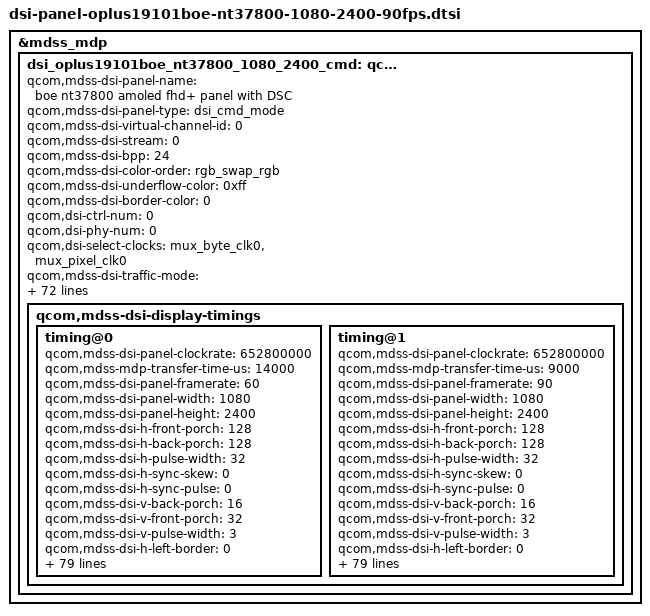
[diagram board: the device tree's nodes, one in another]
&mdss_mdp {
	dsi_oplus19101boe_nt37800_1080_2400_cmd: qcom,mdss_dsi_oplus19101boe_nt37800_1080_2400_cmd {
		qcom,mdss-dsi-panel-name =
		  "boe nt37800 amoled fhd+ panel with DSC";
		qcom,mdss-dsi-panel-type = "dsi_cmd_mode";
		qcom,mdss-dsi-virtual-channel-id = <0>;
		qcom,mdss-dsi-stream = <0>;
		qcom,mdss-dsi-bpp = <24>;
		qcom,mdss-dsi-color-order = "rgb_swap_rgb";
		qcom,mdss-dsi-underflow-color = <0xff>;
		qcom,mdss-dsi-border-color = <0>;

		qcom,dsi-ctrl-num = <0>;
		qcom,dsi-phy-num = <0>;
		qcom,dsi-select-clocks = "src_byte_clk0", "src_pixel_clk0";

		qcom,mdss-dsi-traffic-mode = "non_burst_sync_event";
		qcom,mdss-dsi-lane-map = "lane_map_0123";
		qcom,mdss-dsi-bllp-eof-power-mode;
		qcom,mdss-dsi-bllp-power-mode;
		qcom,mdss-dsi-lane-0-state;
		qcom,mdss-dsi-lane-1-state;
		qcom,mdss-dsi-lane-2-state;
		qcom,mdss-dsi-lane-3-state;
		qcom,mdss-dsi-dma-trigger = "trigger_sw";
		qcom,mdss-dsi-mdp-trigger = "none";
		qcom,mdss-dsi-reset-sequence = <1 10>, <0 10>, <1 10>;
		qcom,mdss-dsi-te-pin-select = <1>;
		qcom,mdss-dsi-wr-mem-start = <0x2c>;
		qcom,mdss-dsi-wr-mem-continue = <0x3c>;
		qcom,mdss-dsi-te-dcs-command = <1>;
		qcom,mdss-dsi-te-check-enable;
		qcom,mdss-dsi-te-using-te-pin;
		//qcom,mdss-dsi-lp11-init;
		qcom,mdss-dsi-panel-hdr-enabled;
		qcom,mdss-dsi-panel-hdr-color-primaries = <15000 15500 34000
			16000 13250 34500 7500 3000>;
		qcom,mdss-dsi-panel-peak-brightness = <4300000>;
		qcom,mdss-dsi-panel-blackness-level = <1023>;
		qcom,mdss-pan-physical-width-dimension = <68>;
		qcom,mdss-pan-physical-height-dimension = <152>;
		qcom,esd-check-enabled;
		qcom,mdss-dsi-panel-status-check-mode = "reg_read";
		qcom,mdss-dsi-panel-status-command = [06 01 00 01 05 00 02 0A 00];
		qcom,mdss-dsi-panel-status-command-state = "dsi_hs_mode";
		qcom,mdss-dsi-panel-status-value = <0x9C>;
		qcom,mdss-dsi-panel-status-read-length = <1>;

		qcom,mdss-dsi-display-timings {
			timing@0{
				qcom,mdss-dsi-panel-clockrate = <652800000>;
				qcom,mdss-mdp-transfer-time-us = <14000>;
				qcom,mdss-dsi-panel-framerate = <60>; /* 60 FPS */
				qcom,mdss-dsi-panel-width = <1080>;
				qcom,mdss-dsi-panel-height = <2400>;
				qcom,mdss-dsi-h-front-porch = <128>;
				qcom,mdss-dsi-h-back-porch = <128>;
				qcom,mdss-dsi-h-pulse-width = <32>;
				qcom,mdss-dsi-h-sync-skew = <0>;
				qcom,mdss-dsi-h-sync-pulse = <0>;
				qcom,mdss-dsi-v-back-porch = <16>;
				qcom,mdss-dsi-v-front-porch = <32>;
				qcom,mdss-dsi-v-pulse-width = <3>;
				qcom,mdss-dsi-h-left-border = <0>;
				qcom,mdss-dsi-h-right-border = <0>;
				qcom,mdss-dsi-v-top-border = <0>;
				qcom,mdss-dsi-v-bottom-border = <0>;
				qcom,mdss-dsi-panel-jitter = <0x4 0x1>;
				oplus,fod-on-vblank = <0>;
				oplus,fod-off-vblank = <0>;
				qcom,mdss-dsi-timing-switch-command = [
					39 01 00 00 00 00 06 F0 55 AA 52 08 00 /* 60 FPS */
					15 01 00 00 00 00 02 6F 0E
					15 01 00 00 00 00 02 BA 18
					15 01 00 00 00 00 02 6F 03
					39 01 00 00 00 00 04 C0 80 00 00
					39 01 00 00 10 00 02 26 01 /* 60 FPS */
				];
				qcom,mdss-dsi-on-command = [
					39 01 00 00 00 00 05 FF AA 55 A5 80
					15 01 00 00 00 00 02 6F 64
					15 01 00 00 00 00 02 F4 06
					/* 101.6Mhz */
					39 01 00 00 00 00 05 FF AA 55 A5 81
					15 01 00 00 00 00 02 6F 05
					15 01 00 00 00 00 02 FD 00
					15 01 00 00 00 00 02 6F 06
					15 01 00 00 00 00 02 FD D8
					39 01 00 00 00 00 06 F0 55 AA 52 08 00
					39 01 00 00 00 00 09 BA 01 D4 00 08 00 08 80 01
					15 01 00 00 00 00 02 6F 08
					39 01 00 00 00 00 09 BA 01 D4 00 08 00 08 00 10
					15 01 00 00 00 00 02 6F 10
					39 01 00 00 00 00 0F BA 01 D4 00 08 00 08 02 30 00 08 00 08 00 00
					39 01 00 00 00 00 09 BB 01 D4 00 08 00 08 00 31
					39 01 00 00 00 00 03 C1 00 70
					39 01 00 00 00 00 03 C0 76 33
					39 01 00 00 00 00 06 F0 55 AA 52 08 03
					39 01 00 00 00 00 0B B2 00 00 0A 06 01 00 00 0A 06 01
					39 01 00 00 00 00 0B B3 00 00 00 04 26 00 00 00 04 26
					39 01 00 00 00 00 16 B6 03 00 00 00 00 00 00 00 08 00 00 00 00 00 08 00 00 00 00 00 00
					39 01 00 00 00 00 08 BB 11 00 23 63 00 23 63
					39 01 00 00 00 00 08 BC 22 10 19 5A 00 19 5A
					39 01 00 00 00 00 06 F0 55 AA 52 08 01
					39 01 00 00 00 00 03 B3 14 14
					39 01 00 00 00 00 07 B7 1A 1A 1A 1A 1A 1A
					39 01 00 00 00 00 08 D2 00 41 1F 41 25 00 67
					/* mipi 652.8Mhz */
					39 01 00 00 00 00 05 ff aa 55 a5 81
					15 01 00 00 00 00 02 6f 09
					15 01 00 00 00 00 02 fd ac
					39 01 00 00 00 00 06 f0 55 aa 52 08 01
					39 01 00 00 00 00 08 c3 99 00 fc 0f 21 01 00
					/* DVDD strong */
					39 01 00 00 00 00 05 FF AA 55 A5 81
					15 01 00 00 00 00 02 FB 20
					15 01 00 00 00 00 02 6F 06
					15 01 00 00 00 00 02 FB 04
					15 01 00 00 00 00 02 6F 09
					15 01 00 00 00 00 02 FB 04
					/*AVEE pump*/
					39 01 00 00 00 00 06 F0 55 AA 52 08 01
					39 01 00 00 00 00 03 B2 02 02
					39 01 00 00 00 00 02 CE 04
					/* Fast Discharge */
					39 01 00 00 00 00 06 F0 55 AA 52 08 01
					39 01 00 00 00 00 02 C7 FA
					/* HW Round */
					39 01 00 00 00 00 06 F0 55 AA 52 08 07
					15 01 00 00 00 00 02 C0 11
					39 01 00 00 00 00 27 C1 60 3C 03 10 F7 78 05 F1 3F FD D2 A0 3F FB CF E8 00 00 63 10 90 1A 00 1B 00 00 76 1C 00 00 00 00 1A 1C F7 FF FF FF
					39 01 00 00 00 00 27 C2 48 3C 01 69 FC 24 02 A4 3F FD 61 7C 3F FE 5E C8 00 00 40 60 24 4F 00 00 1D 00 1A 6C F7 FF FF F7 FF FF F7 FF FF FF
					39 01 00 00 00 00 27 C3 64 00 03 10 07 A8 04 C9 3F FC FC 40 00 03 03 C0 00 00 00 00 00 1C 90 1B 43 90 76 5F 90 00 43 90 1A 5E F7 FF FF FF
					39 01 00 00 00 00 27 C4 4C 00 01 90 04 10 02 A4 3F FC 08 60 00 00 00 00 00 00 00 00 00 50 80 00 F2 90 1A 42 90 00 43 90 1A 5E F7 FF FF FF
					39 01 00 00 00 00 27 C5 6A 3C 02 D9 F8 68 05 10 00 00 CD 08 00 05 44 50 7F FF 63 61 00 00 93 C2 44 94 1A 5F 94 1B 44 94 36 5E F7 FF FF FF
					39 01 00 00 00 00 27 C6 4A 3C 02 D9 FA F0 02 40 00 03 D3 98 00 00 B7 F0 7F FF 8C 22 D0 51 84 1B F2 94 37 43 F7 FF FF F7 FF FF F7 FF FF FF
					39 01 00 00 00 00 27 C7 66 00 02 71 07 08 05 10 00 00 18 C8 3F F9 FF 90 00 00 00 00 00 1B 03 C2 00 04 1A 1B 04 1B 00 04 37 1B F7 FF FF FF
					39 01 00 00 00 00 27 C8 46 00 05 F1 06 18 01 90 00 01 BC F0 3F FE 03 80 00 00 00 00 00 02 04 1B 1C 04 37 6D F7 FF FF F7 FF FF F7 FF FF FF
					39 01 00 00 00 00 27 C9 41 00 03 C1 00 00 03 C1 3F FF 17 42 3F FF 17 42 00 00 0E 17 81 09 00 43 24 00 62 43 F7 FF FF F7 FF FF F7 FF FF FF
					39 01 00 00 00 00 27 CA 4D 00 03 C1 00 00 03 C1 3F FF 17 42 00 00 00 00 00 00 00 00 00 15 00 43 44 00 62 63 F7 FF FF F7 FF FF F7 FF FF FF
					39 01 00 00 00 00 27 CB 4B 00 03 C1 00 00 03 C1 00 00 00 00 00 00 00 00 7F FF F1 E8 7F 15 00 63 44 00 82 63 F7 FF FF F7 FF FF F7 FF FF FF
					39 01 00 00 00 00 27 CC 47 00 03 C1 00 00 03 C1 00 00 00 00 3F FF 17 42 00 00 00 00 00 09 00 63 24 00 82 43 F7 FF FF F7 FF FF F7 FF FF FF
					39 01 00 00 00 00 27 CD 00 00 00 00 00 00 00 00 00 00 00 00 00 00 00 00 00 00 00 00 00 00 F7 FF FF F7 FF FF F7 FF FF F7 FF FF F7 FF FF FF
					39 01 00 00 00 00 27 CE 00 00 00 00 00 00 00 00 00 00 00 00 00 00 00 00 00 00 00 00 00 00 F7 FF FF F7 FF FF F7 FF FF F7 FF FF F7 FF FF FF
					39 01 00 00 00 00 27 CF 00 00 00 00 00 00 00 00 00 00 00 00 00 00 00 00 00 00 00 00 00 00 F7 FF FF F7 FF FF F7 FF FF F7 FF FF F7 FF FF FF
					39 01 00 00 00 00 27 D0 00 00 00 00 00 00 00 00 00 00 00 00 00 00 00 00 00 00 00 00 00 00 F7 FF FF F7 FF FF F7 FF FF F7 FF FF F7 FF FF FF  /* HW Round */
					39 01 00 00 00 00 05 FF AA 55 A5 80
					15 01 00 00 00 00 02 6F 0A
					15 01 00 00 00 00 02 FC 02
					39 01 00 00 00 00 05 FF AA 55 A5 00
					39 01 00 00 00 00 06 F0 55 AA 52 08 00
					15 01 00 00 00 00 02 B2 01
					15 01 00 00 00 00 02 6F 0E
					15 01 00 00 00 00 02 BA 18
					15 01 00 00 00 00 02 6F 03
					39 01 00 00 00 00 04 C0 80 00 00
					39 01 00 00 00 00 02 26 01
					15 01 00 00 00 00 01 35
					39 01 00 00 00 00 05 3B 00 08 00 08
					15 01 00 00 00 00 02 53 20
					39 01 00 00 00 00 05 51 00 00 0F FF
					39 01 00 00 00 00 05 2A 00 00 04 37
					39 01 00 00 00 00 05 2b 00 00 09 5F
					39 01 00 00 00 00 13 93 89 28 00 14 02 00 02 0e 01 e8 00 07 05 0e 05 16 10 f0
					15 01 00 00 00 00 02 90 01
					15 01 00 00 00 00 02 03 11
					05 01 00 00 00 00 01 2c
					39 01 00 00 00 00 06 F0 55 AA 52 08 00
					39 01 00 00 00 00 03 C0 76 33
					39 01 00 00 00 00 06 F0 55 AA 52 08 01
					39 01 00 00 00 00 04 D2 00 41 10
					05 01 00 00 A0 00 01 11
					];
				qcom,mdss-dsi-post-on-backlight = [
					05 01 00 00 00 00 01 29
					];
				qcom,mdss-dsi-off-command = [
					39 01 00 00 00 00 06 F0 55 AA 52 08 01
					39 01 00 00 00 00 02 CE 0C
					05 01 00 00 0A 00 01 28
					05 01 00 00 78 00 01 10];
				qcom,mdss-dsi-lp1-command = [    /* AOD ON */
					39 01 00 00 00 00 06 F0 55 AA 52 08 00  /*Need 90 FPS when AOD in*/
					15 01 00 00 00 00 02 6F 03
					39 01 00 00 00 00 04 C0 00 00 00
					15 01 00 00 14 00 02 26 02  /* Need 90 FPS when AOD in*/
					05 01 00 00 00 00 01 39
					15 01 00 00 00 00 02 65 01
					05 01 00 00 00 00 01 2C
					];
				qcom,mdss-dsi-nolp-command = [    /* AOD OFF */
					39 01 00 00 00 00 06 F0 55 AA 52 08 00 /* 60 FPS */
					15 01 00 00 00 00 02 6F 0E
					15 01 00 00 00 00 02 BA 18
					15 01 00 00 00 00 02 6F 03
					39 01 00 00 00 00 04 C0 80 00 00
					39 01 00 00 00 00 02 26 01 /* 60 FPS */
					15 01 00 00 00 00 02 65 00
					05 01 00 00 00 00 01 38
					05 01 00 00 00 00 01 2C
					];
				qcom,mdss-dsi-aod-hbm-on-command = [  /*AOD->HBM ON PANEL FINGERPRINT OFF*/
					39 01 00 00 00 00 06 F0 55 AA 52 08 00 /* 60 FPS */
					15 01 00 00 00 00 02 6F 0E
					15 01 00 00 00 00 02 BA 18
					15 01 00 00 00 00 02 6F 03
					39 01 00 00 00 00 04 C0 80 00 00
					39 01 00 00 00 00 02 26 01 /* 60 FPS */
					15 01 00 00 00 00 02 65 00
					05 01 00 00 00 00 01 38
					05 01 00 00 00 00 01 2C
					39 01 00 00 00 00 03 51 0F FF
				];
				qcom,mdss-dsi-aod-hbm-off-command = [  /*AOD->HBM ON PANEL FINGERPRINT OFF*/
					39 01 00 00 00 00 06 F0 55 AA 52 08 00  /*Need 90 FPS when AOD in*/
					15 01 00 00 00 00 02 6F 03
					39 01 00 00 00 00 04 C0 00 00 00
					15 01 00 00 14 00 02 26 02  /* Need 90 FPS when AOD in*/
					05 01 00 00 00 00 01 39
					15 01 00 00 00 00 02 65 01
					05 01 00 00 00 00 01 2C
					39 01 00 00 00 00 03 51 00 01
				];
				qcom,mdss-dsi-hbm-on-command = [
					39 01 00 00 22 00 03 51 0F FF
					];
				qcom,mdss-dsi-normal-hbm-on-command = [
					39 01 00 00 00 00 03 51 0F FF
					];
				qcom,mdss-dsi-aod-high-mode-command = [
					/* AOD 50nit */
					39 01 00 00 00 00 06 F0 55 AA 52 08 00
					15 01 00 00 00 00 02 6F 24
					39 01 00 00 00 00 0B B4 00 28 00 28 00 28 00 28 00 28
					];
				qcom,mdss-dsi-aod-low-mode-command = [
					/* AOD 10nit */
					39 01 00 00 00 00 06 F0 55 AA 52 08 00
					15 01 00 00 00 00 02 6F 24
					39 01 00 00 00 00 0B B4 07 80 07 80 07 80 07 80 07 80
					];
				qcom,mdss-dsi-seed-0-command = [
					39 01 00 00 00 00 02 55 80
					39 01 00 00 00 00 06 F0 55 AA 52 08 00
					39 01 00 00 00 00 19 CC 31 33 32 33 33 34 35 35 36 37 36 37 38 38 37 36 33 50 60 70 58 68 78 77
					39 01 00 00 00 00 12 CD 2E 6A 78 51 44 7A 2F 2C 7D 2D 05 63 36 5D 73 48 26
					39 01 00 00 00 00 68 CE 00 6B 49 55 52 57 5B 5F 60 60 60 5C 5A 5A 56 52 52 54 97 4E 43 45 49 4D 47 47 56 5E 57 63 7B 85 88 87 74 5E 41 4B 56 3F 45 44 3D 3A 3D 31 36 3C 37 37 38 3D 43 41 43 53 57 5C 60 5F 60 5F 59 58 58 53 55 58 56 1A 45 3B 39 3E 38 43 43 46 4C 47 4A 50 4E 52 53 4D 59 3F 48 54 5A 54 53 4C 51 50 4B 48 45 3F 39 37 3C
					39 01 00 00 00 00 69 CF 40 40 40 40 40 40 40 40 40 40 40 40 40 40 40 40 40 40 40 40 40 40 40 40 40 40 40 40 40 40 40 40 40 40 40 40 40 40 40 40 40 40 40 40 40 40 40 40 40 40 40 40 40 40 40 40 40 40 40 40 40 40 40 40 40 40 40 40 40 40 40 40 40 40 40 40 40 40 40 40 40 40 40 40 40 40 40 40 40 40 40 40 40 40 40 40 40 40 40 40 40 40 40 40
					39 01 00 00 00 00 07 D0 01 00 FE 77 04 1D
					39 01 00 00 00 00 2e D1 4F 4B 40 50 53 53 50 62 4A 70 7F 7F 7F 7F 77 69 40 41 42 40 42 61 40 40 77 55 55 77 65 66 62 66 51 55 45 55 00 06 0C 03 09 0F 68 88 00
					39 01 00 00 00 00 34 D2 01 08 40 83 88 88 83 83 7C 76 73 6D 7C 7A 7C 80 87 87 89 83 8A 85 82 7B 7D 7B 7E 8F 82 84 84 82 7F 7E 7A 56 5F 63 6D 80 92 99 9E B1 8B 84 80 7C 7A 7F 88
					39 01 00 00 00 00 07 D3 30 52 74 76 50 10
					39 01 00 00 00 00 1a D4 0F 76 76 05 0D 14 0F 18 1F 05 0D 14 03 07 0A A0 55 FF 79 44 12 00 00 80 00
					39 01 00 00 00 00 67 D5 00 00 00 00 00 00 40 40 40 40 40 40 40 40 40 40 40 40 40 40 40 40 40 40 40 40 40 40 40 40 40 40 40 40 40 40 40 40 40 40 40 40 40 40 40 40 40 40 40 40 40 40 40 40 40 40 40 40 40 40 40 40 40 40 40 40 40 40 40 40 40 40 40 40 40 40 40 40 40 40 40 40 40 40 40 40 40 40 40 40 40 40 40 40 40 40 40 40 40 40 40 40
					39 01 00 00 00 00 4e D6 00 00 00 00 00 00 00 00 00 00 00 00 40 40 40 40 40 40 40 40 40 40 40 40 40 40 40 40 40 40 40 40 40 40 40 40 40 40 40 40 40 40 40 40 40 40 40 40 40 40 40 40 40 40 40 40 40 40 40 40 40 40 40 40 40 40 40 40 40 40 40 40 40 40 40 40 40
					39 01 00 00 00 00 32 D7 30 34 3A 3C 3B 3D 41 48 4D 46 41 45 3D 38 3B 3C 3D 3D 40 45 47 44 41 43 3D 3C 3C 3C 3E 3C 3F 42 42 42 42 42 3E 3E 3E 3E 3F 3E 3F 41 41 41 41 41 3F
					39 01 00 00 00 00 19 DE 33 63 33 33 33 30 30 33 33 33 30 33 00 00 00 00 00 00 00 00 00 00 00 00
					];
				qcom,mdss-dsi-seed-1-command = [
					39 01 00 00 00 00 02 55 80
					39 01 00 00 00 00 06 F0 55 AA 52 08 00
					39 01 00 00 00 00 19 CC 2D 2A 30 2B 2C 2B 2C 2C 2C 2E 2E 2F 2E 2D 2B 29 27 50 60 70 58 68 78 77
					39 01 00 00 00 00 12 CD 22 50 67 39 22 2D 71 73 21 6A 4A 42 6E 0D 7C 54 45
					39 01 00 00 00 00 68 CE 00 5A 60 5F 4B 51 4A 4B 46 44 46 42 41 3C 39 38 3A 3F 4B 45 5A 4F 4D 55 52 4B 54 64 65 6E 6D 6A 66 61 5D 39 37 46 3D 3B 37 3D 36 34 3F 3E 40 3D 40 40 41 42 39 3F 5A 45 49 42 47 45 41 4C 4A 49 45 43 41 40 40 56 4E 59 4A 4C 4A 50 43 43 46 41 3F 3C 39 38 3B 3E 56 4F 5F 49 49 43 44 3B 3D 40 3D 40 3C 3D 3C 3D 42
					39 01 00 00 00 00 69 CF 40 40 40 40 40 40 40 40 40 40 40 40 40 40 40 40 40 40 40 40 40 40 40 40 40 40 40 40 40 40 40 40 40 40 40 40 40 40 40 40 40 40 40 40 40 40 40 40 40 40 40 40 40 40 40 40 40 40 40 40 40 40 40 40 40 40 40 40 40 40 40 40 40 40 40 40 40 40 40 40 40 40 40 40 40 40 40 40 40 40 40 40 40 40 40 40 40 40 40 40 40 40 40 40
					39 01 00 00 00 00 07 D0 01 00 FE 77 04 1D
					39 01 00 00 00 00 2e D1 60 61 66 72 72 77 7F 72 72 7F 7F 7F 7F 7F 74 5F 51 4F 55 5F 68 66 63 5E 66 46 44 44 54 55 42 50 51 75 74 57 00 06 0C 03 09 0F 68 88 00
					39 01 00 00 00 00 34 D2 01 00 40 8B 8E 8E 88 83 77 69 56 4E 58 64 6F 85 92 94 8E 8F 85 74 6E 66 79 7A 79 9A 7B 80 81 81 80 8F 60 2D 06 38 4F 87 A7 AF A0 B1 87 76 6E 6A 80 8F 9E
					39 01 00 00 00 00 07 D3 30 52 74 76 50 10
					39 01 00 00 00 00 1a D4 0F 76 76 05 0D 14 0F 18 1F 05 0D 14 03 07 0A A0 55 FF 79 44 12 00 00 80 00
					39 01 00 00 00 00 67 D5 00 00 00 00 00 00 40 40 40 40 40 40 40 40 40 40 40 40 40 40 40 40 40 40 40 40 40 40 40 40 40 40 40 40 40 40 40 40 40 40 40 40 40 40 40 40 40 40 40 40 40 40 40 40 40 40 40 40 40 40 40 40 40 40 40 40 40 40 40 40 40 40 40 40 40 40 40 40 40 40 40 40 40 40 40 40 40 40 40 40 40 40 40 40 40 40 40 40 40 40 40 40
					39 01 00 00 00 00 4e D6 00 00 00 00 00 00 00 00 00 00 00 00 40 40 40 40 40 40 40 40 40 40 40 40 40 40 40 40 40 40 40 40 40 40 40 40 40 40 40 40 40 40 40 40 40 40 40 40 40 40 40 40 40 40 40 40 40 40 40 40 40 40 40 40 40 40 40 40 40 40 40 40 40 40 40 40 40
					39 01 00 00 00 00 32 D7 30 39 3C 40 43 46 4B 4F 53 39 49 4E 43 38 3C 3F 41 41 46 4A 4B 3D 44 48 3F 38 3C 3E 40 3D 42 45 44 40 40 42 3C 3C 3E 3F 40 3E 41 42 42 40 40 41 3E
					39 01 00 00 00 00 19 DE 43 45 33 43 40 00 33 34 33 33 37 43 00 00 00 00 00 00 00 00 00 00 00 00
					];
				qcom,mdss-dsi-spr-0-command = [
					39 01 00 00 00 00 06 F0 55 AA 52 08 07
					39 01 00 00 00 00 07 B0 A4 40 70 60 00 00
					39 01 00 00 00 00 18 B1 08 18 00 18 08 00 00 00 00 00 00 00 00 00 00 00 00 00 00 00 00 00 00
					39 01 00 00 00 00 B5 B2 20 20 20 20 20 20 20 20 20 20 20 20 20 20 20 20 20 20 20 20 20 20 20 20 20 20 20 20 20 20 20 20 20 20 20 20 20 20 20 20 20 20 20 20 20 20 20 20 20 20 20 20 20 20 32 32 32 32 32 32 32 32 32 00 00 00 00 00 00 00 00 00 32 32 32 32 32 32 32 32 32 00 00 00 00 00 00 00 00 00 32 32 32 32 32 32 32 32 32 00 00 00 00 00 00 00 00 00 32 32 32 32 32 32 32 32 32 00 00 00 00 00 00 00 00 00 32 32 32 32 32 32 32 32 32 00 00 00 00 00 00 00 00 00 32 32 32 32 32 32 32 32 32 00 00 00 00 00 00 00 00 00 00 00 20 00 20 00 00 00 00 00 32 00 00 00 32 00 00 00
					39 01 00 00 00 00 5B B3 00 00 00 00 00 00 00 00 00 00 00 00 00 00 00 00 00 00 00 00 00 00 00 00 00 00 00 00 00 00 00 00 00 00 00 00 00 00 00 00 00 00 00 00 00 00 00 00 00 00 00 00 00 00 00 00 00 00 00 00 00 00 00 00 00 00 00 00 00 00 00 00 00 00 00 00 00 00 00 00 00 00 00 00 00 00 00 00 00 00
					39 01 00 00 00 00 1B B4 C0 00 00 00 00 00 00 00 00 00 00 00 00 00 80 80 80 80 40 80 80 80 80 80 40 80
					39 01 00 00 00 00 49 B5 00 00 00 00 00 00 00 00 00 00 00 00 00 00 00 00 00 00 00 00 00 00 04 00 00 00 00 00 00 00 00 00 00 00 00 00 00 00 00 00 00 00 00 00 00 00 00 00 00 00 00 00 00 00 00 00 00 00 00 00 00 00 00 00 00 00 00 00 00 00 00 00
					39 01 00 00 00 00 25 B6 00 00 00 00 00 00 00 00 00 00 00 00 00 00 00 00 00 00 00 00 00 00 00 00 E0 00 E0 00 00 00 E0 00 E0 00 00 00
					39 01 00 00 00 00 50 B7 24 84 00 08 01 08 01 00 00 00 00 00 00 00 00 00 00 00 00 00 00 00 00 00 00 00 00 00 00 00 00 00 00 00 00 00 00 00 00 00 00 00 00 FD 58 0E A5 78 2A 1A 77 FE CF 7E 0D E5 B2 B7 87 CC 14 80 80 80 80 80 80 80 80 80 80 80 80 80 80 80 80 80 80
					39 01 00 00 00 00 58 B8 00 00 00 00 00 00 00 00 00 00 00 00 00 00 00 00 00 00 00 02 02 00 00 00 00 00 00 00 00 00 00 00 00 00 00 00 00 00 00 00 00 00 00 00 00 00 00 00 00 00 00 00 00 00 00 00 00 00 00 00 00 00 00 00 00 00 00 00 00 00 00 00 00 00 00 00 00 00 00 00 00 00 00 00 00 00 00
					39 01 00 00 00 00 C1 B9 00 00 00 00 00 00 00 00 00 00 00 00 00 00 00 00 00 00 00 00 00 00 00 00 00 00 00 00 00 00 00 00 00 00 00 00 00 00 00 00 00 00 00 00 00 00 00 00 00 00 00 00 00 00 00 00 00 00 00 00 00 00 00 00 00 00 00 00 00 00 00 00 00 00 00 00 00 00 00 00 00 00 00 00 00 00 00 00 00 00 00 00 00 00 00 00 00 00 00 00 00 00 00 00 00 00 00 00 00 00 00 00 00 00 00 00 00 00 00 00 00 00 00 00 00 00 00 00 00 00 00 00 00 00 00 00 00 00 00 00 00 00 00 00 00 00 00 00 00 00 00 00 00 00 00 00 00 00 00 00 00 00 00 00 00 00 00 00 00 00 00 00 00 00 00 00 00 00 00 00 00 00 00 00 00 00 00 00 00 00 00 00
					39 01 00 00 00 00 20 BA 00 00 00 00 00 00 00 00 00 00 00 00 00 00 00 00 00 00 00 00 00 00 00 00 00 00 00 00 00 00 00
					39 01 00 00 00 00 88 BB 00 00 00 00 00 00 00 00 00 00 00 00 00 00 00 00 00 00 00 00 00 00 00 00 00 00 00 00 00 00 00 00 00 00 00 00 00 00 00 00 00 00 00 00 00 00 00 00 00 00 00 00 00 00 00 00 00 00 00 00 00 00 00 00 00 00 00 00 00 00 00 00 00 00 00 00 00 00 00 00 00 00 00 00 00 00 00 00 00 00 00 00 00 00 00 00 00 00 00 00 00 00 00 00 00 00 00 00 00 00 00 00 00 00 00 00 00 00 00 00 00 00 00 00 00 00 00 00 00 00 00 00 00 00 00
					39 01 00 00 00 00 14 BC 00 00 00 00 00 00 00 00 00 00 00 00 00 00 00 00 00 00 00
					39 01 00 00 00 00 0D BD 00 00 00 00 00 00 00 00 00 00 00 00
					];
				qcom,mdss-dsi-spr-1-command = [
					39 01 00 00 00 00 06 F0 55 AA 52 08 07
					39 01 00 00 00 00 07 B0 A4 40 70 60 00 00
					39 01 00 00 00 00 03 B7 80 90
					39 01 00 00 00 00 02 6F 43
					39 01 00 00 00 00 04 B7 80 70 80
					39 01 00 00 00 00 02 6F 46
					39 01 00 00 00 00 04 B7 80 70 80
					39 01 00 00 00 00 18 B1 0C 1C 00 1C 0C 00 00 00 00 00 00 00 00 00 00 00 00 00 00 00 00 00 00
					39 01 00 00 00 00 B5 B2 22 22 22 22 22 22 22 22 22 22 22 22 22 22 22 22 22 22 00 00 00 00 00 00 00 00 00 22 22 22 22 22 22 22 22 22 22 22 22 22 22 22 22 22 22 00 00 00 00 00 00 00 00 00 3A 3A 3A 3A 3A 3A 3A 3A 3A 05 05 05 05 05 05 05 05 05 3A 3A 3A 3A 3A 3A 3A 3A 3A 05 05 05 05 05 05 05 05 05 00 00 00 00 00 00 00 00 00 00 00 00 00 00 00 00 00 00 3A 3A 3A 3A 3A 3A 3A 3A 3A 05 05 05 05 05 05 05 05 05 3A 3A 3A 3A 3A 3A 3A 3A 3A 05 05 05 05 05 05 05 05 05 00 00 00 00 00 00 00 00 00 00 00 00 00 00 00 00 00 00 00 00 00 00 00 00 00 00 00 00 00 00 00 00 00 00 00 00
					39 01 00 00 00 00 5B B3 00 00 00 00 00 00 00 00 00 00 00 00 00 00 00 00 00 00 00 00 00 00 00 00 00 00 00 00 00 00 00 00 00 00 00 00 00 00 00 00 00 00 00 00 00 00 00 00 00 00 00 00 00 00 00 00 00 00 00 00 00 00 00 00 00 00 00 00 00 00 00 00 00 00 00 00 00 00 00 00 00 00 00 00 00 00 00 00 00 00
					39 01 00 00 00 00 1B B4 C0 00 00 00 00 00 00 00 00 00 00 00 00 00 80 68 80 80 60 80 80 60 80 80 A0 80
					39 01 00 00 00 00 49 B5 00 00 00 00 00 00 00 00 00 00 00 00 00 00 00 00 00 00 00 00 00 00 04 00 00 00 00 00 00 00 00 00 00 00 00 00 00 00 00 00 00 00 00 00 00 00 00 00 00 00 00 00 00 00 00 00 00 00 00 00 00 00 00 00 00 00 00 00 00 00 00 00
					39 01 00 00 00 00 25 B6 00 00 00 00 00 00 00 00 00 00 00 00 00 00 00 00 00 00 00 00 00 00 00 00 E0 00 E0 00 00 00 E0 00 E0 00 00 00
					39 01 00 00 00 00 58 B8 00 00 00 00 00 00 00 00 00 00 00 00 00 00 00 00 00 00 00 02 02 00 00 00 00 00 00 00 00 00 00 00 00 00 00 00 00 00 00 00 00 00 00 00 00 00 00 00 00 00 00 00 00 00 00 00 00 00 00 00 00 00 00 00 00 00 00 00 00 00 00 00 00 00 00 00 00 00 00 00 00 00 00 00 00 00 00
					39 01 00 00 00 00 C1 B9 00 00 00 00 00 00 00 00 00 00 00 00 00 00 00 00 00 00 00 00 00 00 00 00 00 00 00 00 00 00 00 00 00 00 00 00 00 00 00 00 00 00 00 00 00 00 00 00 00 00 00 00 00 00 00 00 00 00 00 00 00 00 00 00 00 00 00 00 00 00 00 00 00 00 00 00 00 00 00 00 00 00 00 00 00 00 00 00 00 00 00 00 00 00 00 00 00 00 00 00 00 00 00 00 00 00 00 00 00 00 00 00 00 00 00 00 00 00 00 00 00 00 00 00 00 00 00 00 00 00 00 00 00 00 00 00 00 00 00 00 00 00 00 00 00 00 00 00 00 00 00 00 00 00 00 00 00 00 00 00 00 00 00 00 00 00 00 00 00 00 00 00 00 00 00 00 00 00 00 00 00 00 00 00 00 00 00 00 00 00 00 00
					39 01 00 00 00 00 20 BA 00 00 00 00 00 00 00 00 00 00 00 00 00 00 00 00 00 00 00 00 00 00 00 00 00 00 00 00 00 00 00
					39 01 00 00 00 00 88 BB 00 00 00 00 00 00 00 00 00 00 00 00 00 00 00 00 00 00 00 00 00 00 00 00 00 00 00 00 00 00 00 00 00 00 00 00 00 00 00 00 00 00 00 00 00 00 00 00 00 00 00 00 00 00 00 00 00 00 00 00 00 00 00 00 00 00 00 00 00 00 00 00 00 00 00 00 00 00 00 00 00 00 00 00 00 00 00 00 00 00 00 00 00 00 00 00 00 00 00 00 00 00 00 00 00 00 00 00 00 00 00 00 00 00 00 00 00 00 00 00 00 00 00 00 00 00 00 00 00 00 00 00 00 00 00
					39 01 00 00 00 00 14 BC 00 00 00 00 00 00 00 00 00 00 00 00 00 00 00 00 00 00 00
					39 01 00 00 00 00 0D BD 00 00 00 00 00 00 00 00 00 00 00 00
					];
				qcom,mdss-dsi-spr-2-command = [
					39 01 00 00 00 00 06 F0 55 AA 52 08 07
					39 01 00 00 00 00 07 B0 A4 40 70 60 00 00
					39 01 00 00 00 00 18 B1 08 18 00 18 08 00 00 00 00 00 00 00 00 00 00 00 00 00 00 00 00 00 00
					39 01 00 00 00 00 B5 B2 20 20 20 20 20 20 20 20 20 20 20 20 20 20 20 20 20 20 20 20 20 20 20 20 20 20 20 20 20 20 20 20 20 20 20 20 20 20 20 20 20 20 20 20 20 20 20 20 20 20 20 20 20 20 03 03 03 03 03 03 03 03 03 00 00 00 00 00 00 00 00 00 03 03 03 03 03 03 03 03 03 00 00 00 00 00 00 00 00 00 03 03 03 03 03 03 03 03 03 00 00 00 00 00 00 00 00 00 03 03 03 03 03 03 03 03 03 00 00 00 00 00 00 00 00 00 03 03 03 03 03 03 03 03 03 00 00 00 00 00 00 00 00 00 03 03 03 03 03 03 03 03 03 00 00 00 00 00 00 00 00 00 00 00 20 00 20 00 00 00 00 00 32 00 00 00 32 00 00 00
					39 01 00 00 00 00 5B B3 00 00 00 00 00 00 00 00 00 00 00 00 00 00 00 00 00 00 00 00 00 00 00 00 00 00 00 00 00 00 00 00 00 00 00 00 00 00 00 00 00 00 00 00 00 00 00 00 00 00 00 00 00 00 00 00 00 00 00 00 00 00 00 00 00 00 00 00 00 00 00 00 00 00 00 00 00 00 00 00 00 00 00 00 00 00 00 00 00 00
					39 01 00 00 00 00 1B B4 C0 00 00 00 00 00 00 00 00 00 00 00 00 00 80 80 80 80 40 80 80 80 80 80 40 80
					39 01 00 00 00 00 49 B5 00 00 00 00 00 00 00 00 00 00 00 00 00 00 00 00 00 00 00 00 00 00 04 00 00 00 00 00 00 00 00 00 00 00 00 00 00 00 00 00 00 00 00 00 00 00 00 00 00 00 00 00 00 00 00 00 00 00 00 00 00 00 00 00 00 00 00 00 00 00 00 00
					39 01 00 00 00 00 25 B6 00 00 00 00 00 00 00 00 00 00 00 00 00 00 00 00 00 00 00 00 00 00 00 00 E0 00 E0 00 00 00 E0 00 E0 00 00 00
					39 01 00 00 00 00 50 B7 24 84 00 08 01 08 01 00 00 00 00 00 00 00 00 00 00 00 00 00 00 00 00 00 00 00 00 00 00 00 00 00 00 00 00 00 00 00 00 00 00 00 00 FD 58 0E A5 78 2A 1A 77 FE CF 7E 0D E5 B2 B7 87 CC 14 80 80 80 80 80 80 80 80 80 80 80 80 80 80 80 80 80 80
					39 01 00 00 00 00 58 B8 00 00 00 00 00 00 00 00 00 00 00 00 00 00 00 00 00 00 00 02 02 00 00 00 00 00 00 00 00 00 00 00 00 00 00 00 00 00 00 00 00 00 00 00 00 00 00 00 00 00 00 00 00 00 00 00 00 00 00 00 00 00 00 00 00 00 00 00 00 00 00 00 00 00 00 00 00 00 00 00 00 00 00 00 00 00 00
					39 01 00 00 00 00 C1 B9 00 00 00 00 00 00 00 00 00 00 00 00 00 00 00 00 00 00 00 00 00 00 00 00 00 00 00 00 00 00 00 00 00 00 00 00 00 00 00 00 00 00 00 00 00 00 00 00 00 00 00 00 00 00 00 00 00 00 00 00 00 00 00 00 00 00 00 00 00 00 00 00 00 00 00 00 00 00 00 00 00 00 00 00 00 00 00 00 00 00 00 00 00 00 00 00 00 00 00 00 00 00 00 00 00 00 00 00 00 00 00 00 00 00 00 00 00 00 00 00 00 00 00 00 00 00 00 00 00 00 00 00 00 00 00 00 00 00 00 00 00 00 00 00 00 00 00 00 00 00 00 00 00 00 00 00 00 00 00 00 00 00 00 00 00 00 00 00 00 00 00 00 00 00 00 00 00 00 00 00 00 00 00 00 00 00 00 00 00 00 00 00
					39 01 00 00 00 00 20 BA 00 00 00 00 00 00 00 00 00 00 00 00 00 00 00 00 00 00 00 00 00 00 00 00 00 00 00 00 00 00 00
					39 01 00 00 00 00 88 BB 00 00 00 00 00 00 00 00 00 00 00 00 00 00 00 00 00 00 00 00 00 00 00 00 00 00 00 00 00 00 00 00 00 00 00 00 00 00 00 00 00 00 00 00 00 00 00 00 00 00 00 00 00 00 00 00 00 00 00 00 00 00 00 00 00 00 00 00 00 00 00 00 00 00 00 00 00 00 00 00 00 00 00 00 00 00 00 00 00 00 00 00 00 00 00 00 00 00 00 00 00 00 00 00 00 00 00 00 00 00 00 00 00 00 00 00 00 00 00 00 00 00 00 00 00 00 00 00 00 00 00 00 00 00 00
					39 01 00 00 00 00 14 BC 00 00 00 00 00 00 00 00 00 00 00 00 00 00 00 00 00 00 00
					39 01 00 00 00 00 0D BD 00 00 00 00 00 00 00 00 00 00 00 00
					];

				qcom,mdss-dsi-data-dimming-on-command = [
					39 00 00 00 00 00 06 F0 55 AA 52 08 00
					39 00 00 00 00 00 02 B2 80
					39 00 00 00 00 00 1E B4
					   00 00 00 00 00 00 00 00 00 00
					   28 28 28 28 28 28 28 28 28 28
					   28 28 28 28 28 28 28 28 28
					39 00 00 00 00 00 25 B3
					   00 00 00 00 00 00 00 00 00 00
					   00 00 00 00 00 00 00 00 00 00
					   00 00 00 00 00 00 00 00 00 00
					   00 00 06 F4 0F FF
				];
				qcom,mdss-dsi-data-dimming-off-command = [
					39 00 00 00 00 00 06 F0 55 AA 52 08 00
					39 00 00 00 00 00 25 B3
					   00 01 00 80 00 80 00 AF 00 AF
					   00 E5 00 E5 01 5B 01 5B 01 F2
					   01 F2 02 58 02 58 03 00 03 00
					   06 F4 06 F4 0F FF
					39 00 00 00 00 00 02 B2 00
					39 00 00 00 00 00 1E B4
					   99 88 88 66 44 22 00 00 00 00
					   40 40 DF DF 1D 1D FC FC E8 E8
					   8C 8C F2 F2 28 28 28 28 28 2C
				];
				qcom,mdss-dsi-data-dimming-on-command-state = "dsi_hs_mode";
				qcom,mdss-dsi-data-dimming-off-command-state = "dsi_hs_mode";
				qcom,mdss-dsi-aod-hbm-on-command-state = "dsi_lp_mode";
				qcom,mdss-dsi-aod-hbm-off-command-state = "dsi_lp_mode";
				qcom,mdss-dsi-hbm-off-command-state = "dsi_hs_mode";
				qcom,mdss-dsi-lp1-command-state = "dsi_lp_mode";
				qcom,mdss-dsi-nolp-command-state = "dsi_lp_mode";
				qcom,mdss-dsi-post-on-backlight-state = "dsi_hs_mode";
				qcom,mdss-dsi-on-command-state = "dsi_lp_mode";
				qcom,mdss-dsi-off-command-state = "dsi_hs_mode";
				qcom,mdss-dsi-normal-hbm-on-command-state = "dsi_hs_mode";
				qcom,mdss-dsi-aod-high-mode-command-state = "dsi_lp_mode";
				qcom,mdss-dsi-aod-low-mode-command-state = "dsi_lp_mode";
				qcom,mdss-dsi-timing-switch-command-state = "dsi_lp_mode";
				qcom,compression-mode = "dsc";
				qcom,mdss-dsc-slice-height = <20>;
				qcom,mdss-dsc-slice-width = <540>;
				qcom,mdss-dsc-slice-per-pkt = <2>;
				qcom,mdss-dsc-bit-per-component = <8>;
				qcom,mdss-dsc-bit-per-pixel = <8>;
				qcom,mdss-dsc-block-prediction-enable;
			};

			timing@1{
				qcom,mdss-dsi-panel-clockrate = <652800000>;
				qcom,mdss-mdp-transfer-time-us = <9000>;
				qcom,mdss-dsi-panel-framerate = <90>; /* 90 FPS */
				qcom,mdss-dsi-panel-width = <1080>;
				qcom,mdss-dsi-panel-height = <2400>;
				qcom,mdss-dsi-h-front-porch = <128>;
				qcom,mdss-dsi-h-back-porch = <128>;
				qcom,mdss-dsi-h-pulse-width = <32>;
				qcom,mdss-dsi-h-sync-skew = <0>;
				qcom,mdss-dsi-h-sync-pulse = <0>;
				qcom,mdss-dsi-v-back-porch = <16>;
				qcom,mdss-dsi-v-front-porch = <32>;
				qcom,mdss-dsi-v-pulse-width = <3>;
				qcom,mdss-dsi-h-left-border = <0>;
				qcom,mdss-dsi-h-right-border = <0>;
				qcom,mdss-dsi-v-top-border = <0>;
				qcom,mdss-dsi-v-bottom-border = <0>;
				qcom,mdss-dsi-panel-jitter = <0x4 0x1>;
				oplus,fod-on-vblank = <1>;
				oplus,fod-off-vblank = <1>;
				qcom,mdss-dsi-timing-switch-command = [
					39 01 00 00 00 00 06 F0 55 AA 52 08 00
					15 01 00 00 00 00 02 6F 03
					39 01 00 00 00 00 04 C0 00 00 00
					15 01 00 00 00 00 02 26 02
				];
				qcom,mdss-dsi-on-command = [
					39 01 00 00 00 00 05 FF AA 55 A5 80
					15 01 00 00 00 00 02 6F 64
					15 01 00 00 00 00 02 F4 06
					/* OSC 101.6Mhz */
					39 01 00 00 00 00 05 FF AA 55 A5 81
					15 01 00 00 00 00 02 6F 05
					15 01 00 00 00 00 02 FD 00
					15 01 00 00 00 00 02 6F 06
					15 01 00 00 00 00 02 FD D8
					39 01 00 00 00 00 06 F0 55 AA 52 08 00
					39 01 00 00 00 00 09 BA 01 D4 00 08 00 08 80 01
					15 01 00 00 00 00 02 6F 08
					39 01 00 00 00 00 09 BA 01 D4 00 08 00 08 00 10
					15 01 00 00 00 00 02 6F 10
					39 01 00 00 00 00 0F BA 01 D4 00 08 00 08 02 30 00 08 00 08 00 00
					39 01 00 00 00 00 09 BB 01 D4 00 08 00 08 00 31
					39 01 00 00 00 00 03 C1 00 70
					39 01 00 00 00 00 03 C0 76 33
					39 01 00 00 00 00 06 F0 55 AA 52 08 03
					39 01 00 00 00 00 0B B2 00 00 0A 06 01 00 00 0A 06 01
					39 01 00 00 00 00 0B B3 00 00 00 04 26 00 00 00 04 26
					39 01 00 00 00 00 16 B6 03 00 00 00 00 00 00 00 08 00 00 00 00 00 08 00 00 00 00 00 00
					39 01 00 00 00 00 08 BB 11 00 23 63 00 23 63
					39 01 00 00 00 00 08 BC 22 10 19 5A 00 19 5A
					39 01 00 00 00 00 06 F0 55 AA 52 08 01 //VGH
					39 01 00 00 00 00 03 B3 14 14
					39 01 00 00 00 00 07 B7 1A 1A 1A 1A 1A 1A
					39 01 00 00 00 00 08 D2 00 41 1F 41 25 00 67
					/* mipi 652.8Mhz */
					39 01 00 00 00 00 05 ff aa 55 a5 81
					15 01 00 00 00 00 02 6f 09
					15 01 00 00 00 00 02 fd ac
					39 01 00 00 00 00 06 f0 55 aa 52 08 01
					39 01 00 00 00 00 08 c3 99 00 fc 0f 21 01 00
					/* DVDD strong */
					39 01 00 00 00 00 05 FF AA 55 A5 81
					15 01 00 00 00 00 02 FB 20
					15 01 00 00 00 00 02 6F 06
					15 01 00 00 00 00 02 FB 04
					15 01 00 00 00 00 02 6F 09
					15 01 00 00 00 00 02 FB 04
					/*AVEE pump*/
					39 01 00 00 00 00 06 F0 55 AA 52 08 01
					39 01 00 00 00 00 03 B2 02 02
					39 01 00 00 00 00 02 CE 04
					/* Fast Discharge */
					39 01 00 00 00 00 06 F0 55 AA 52 08 01
					39 01 00 00 00 00 02 C7 FA
					/* HW Round */
					39 01 00 00 00 00 06 F0 55 AA 52 08 07
					15 01 00 00 00 00 02 C0 11
					39 01 00 00 00 00 27 C1 60 3C 03 10 F7 78 05 F1 3F FD D2 A0 3F FB CF E8 00 00 63 10 90 1A 00 1B 00 00 76 1C 00 00 00 00 1A 1C F7 FF FF FF
					39 01 00 00 00 00 27 C2 48 3C 01 69 FC 24 02 A4 3F FD 61 7C 3F FE 5E C8 00 00 40 60 24 4F 00 00 1D 00 1A 6C F7 FF FF F7 FF FF F7 FF FF FF
					39 01 00 00 00 00 27 C3 64 00 03 10 07 A8 04 C9 3F FC FC 40 00 03 03 C0 00 00 00 00 00 1C 90 1B 43 90 76 5F 90 00 43 90 1A 5E F7 FF FF FF
					39 01 00 00 00 00 27 C4 4C 00 01 90 04 10 02 A4 3F FC 08 60 00 00 00 00 00 00 00 00 00 50 80 00 F2 90 1A 42 90 00 43 90 1A 5E F7 FF FF FF
					39 01 00 00 00 00 27 C5 6A 3C 02 D9 F8 68 05 10 00 00 CD 08 00 05 44 50 7F FF 63 61 00 00 93 C2 44 94 1A 5F 94 1B 44 94 36 5E F7 FF FF FF
					39 01 00 00 00 00 27 C6 4A 3C 02 D9 FA F0 02 40 00 03 D3 98 00 00 B7 F0 7F FF 8C 22 D0 51 84 1B F2 94 37 43 F7 FF FF F7 FF FF F7 FF FF FF
					39 01 00 00 00 00 27 C7 66 00 02 71 07 08 05 10 00 00 18 C8 3F F9 FF 90 00 00 00 00 00 1B 03 C2 00 04 1A 1B 04 1B 00 04 37 1B F7 FF FF FF
					39 01 00 00 00 00 27 C8 46 00 05 F1 06 18 01 90 00 01 BC F0 3F FE 03 80 00 00 00 00 00 02 04 1B 1C 04 37 6D F7 FF FF F7 FF FF F7 FF FF FF
					39 01 00 00 00 00 27 C9 41 00 03 C1 00 00 03 C1 3F FF 17 42 3F FF 17 42 00 00 0E 17 81 09 00 43 24 00 62 43 F7 FF FF F7 FF FF F7 FF FF FF
					39 01 00 00 00 00 27 CA 4D 00 03 C1 00 00 03 C1 3F FF 17 42 00 00 00 00 00 00 00 00 00 15 00 43 44 00 62 63 F7 FF FF F7 FF FF F7 FF FF FF
					39 01 00 00 00 00 27 CB 4B 00 03 C1 00 00 03 C1 00 00 00 00 00 00 00 00 7F FF F1 E8 7F 15 00 63 44 00 82 63 F7 FF FF F7 FF FF F7 FF FF FF
					39 01 00 00 00 00 27 CC 47 00 03 C1 00 00 03 C1 00 00 00 00 3F FF 17 42 00 00 00 00 00 09 00 63 24 00 82 43 F7 FF FF F7 FF FF F7 FF FF FF
					39 01 00 00 00 00 27 CD 00 00 00 00 00 00 00 00 00 00 00 00 00 00 00 00 00 00 00 00 00 00 F7 FF FF F7 FF FF F7 FF FF F7 FF FF F7 FF FF FF
					39 01 00 00 00 00 27 CE 00 00 00 00 00 00 00 00 00 00 00 00 00 00 00 00 00 00 00 00 00 00 F7 FF FF F7 FF FF F7 FF FF F7 FF FF F7 FF FF FF
					39 01 00 00 00 00 27 CF 00 00 00 00 00 00 00 00 00 00 00 00 00 00 00 00 00 00 00 00 00 00 F7 FF FF F7 FF FF F7 FF FF F7 FF FF F7 FF FF FF
					39 01 00 00 00 00 27 D0 00 00 00 00 00 00 00 00 00 00 00 00 00 00 00 00 00 00 00 00 00 00 F7 FF FF F7 FF FF F7 FF FF F7 FF FF F7 FF FF FF  /* HW Round */
					39 01 00 00 00 00 05 FF AA 55 A5 80
					15 01 00 00 00 00 02 6F 0A
					15 01 00 00 00 00 02 FC 02
					39 01 00 00 00 00 05 FF AA 55 A5 00
					39 01 00 00 00 00 06 F0 55 AA 52 08 00
					15 01 00 00 00 00 02 B2 01
					15 01 00 00 00 00 02 6F 03
					39 01 00 00 00 00 04 C0 00 00 00
					15 01 00 00 00 00 02 26 02
					15 01 00 00 00 00 01 35
					39 01 00 00 00 00 05 3B 00 08 00 08
					15 01 00 00 00 00 02 53 20
					39 01 00 00 00 00 05 51 00 00 0F FF
					39 01 00 00 00 00 05 2A 00 00 04 37
					39 01 00 00 00 00 05 2b 00 00 09 5F
					39 01 00 00 00 00 13 93 89 28 00 14 02 00 02 0e 01 e8 00 07 05 0e 05 16 10 f0
					15 01 00 00 00 00 02 90 01
					15 01 00 00 00 00 02 03 11
					05 01 00 00 00 00 01 2c
					39 01 00 00 00 00 06 F0 55 AA 52 08 00
					39 01 00 00 00 00 03 C0 76 33
					39 01 00 00 00 00 06 F0 55 AA 52 08 01
					39 01 00 00 00 00 04 D2 00 41 10
					05 01 00 00 78 00 01 11
					];
				qcom,mdss-dsi-post-on-backlight = [
					05 01 00 00 00 00 01 29
					];
				qcom,mdss-dsi-off-command = [
					39 01 00 00 00 00 06 F0 55 AA 52 08 01
					39 01 00 00 00 00 02 CE 0C
					05 01 00 00 0A 00 01 28
					05 01 00 00 78 00 01 10];
				qcom,mdss-dsi-lp1-command = [    /* AOD ON */
					05 01 00 00 00 00 01 39
					15 01 00 00 00 00 02 65 01
					05 01 00 00 00 00 01 2C
					];
				qcom,mdss-dsi-nolp-command = [    /* AOD OFF */
					15 01 00 00 00 00 02 65 00
					05 01 00 00 00 00 01 38
					05 01 00 00 00 00 01 2C
					];
				qcom,mdss-dsi-aod-hbm-on-command = [  /*AOD->HBM ON PANEL FINGERPRINT OFF*/
					15 01 00 00 00 00 02 65 00
					05 01 00 00 00 00 01 38
					05 01 00 00 00 00 01 2C
					39 01 00 00 00 00 03 51 0F FF
				];
				qcom,mdss-dsi-aod-hbm-off-command = [  /*AOD->HBM ON PANEL FINGERPRINT OFF*/
					05 01 00 00 00 00 01 39
					15 01 00 00 00 00 02 65 01
					05 01 00 00 00 00 01 2C
					39 01 00 00 00 00 03 51 00 01
				];
				qcom,mdss-dsi-hbm-on-command = [
					39 01 00 00 22 00 03 51 0F FF
					];
				qcom,mdss-dsi-normal-hbm-on-command = [
					39 01 00 00 00 00 03 51 0F FF
					];
				qcom,mdss-dsi-aod-high-mode-command = [
					/* AOD 50nit */
					39 01 00 00 00 00 06 F0 55 AA 52 08 00
					15 01 00 00 00 00 02 6F 24
					39 01 00 00 00 00 0B B4 00 28 00 28 00 28 00 28 00 28
					];
				qcom,mdss-dsi-aod-low-mode-command = [
					/* AOD 10nit */
					39 01 00 00 00 00 06 F0 55 AA 52 08 00
					15 01 00 00 00 00 02 6F 24
					39 01 00 00 00 00 0B B4 07 80 07 80 07 80 07 80 07 80
					];
				qcom,mdss-dsi-seed-0-command = [
					39 01 00 00 00 00 02 55 80
					39 01 00 00 00 00 06 F0 55 AA 52 08 00
					39 01 00 00 00 00 19 CC 31 33 32 33 33 34 35 35 36 37 36 37 38 38 37 36 33 50 60 70 58 68 78 77
					39 01 00 00 00 00 12 CD 2E 6A 78 51 44 7A 2F 2C 7D 2D 05 63 36 5D 73 48 26
					39 01 00 00 00 00 68 CE 00 6B 49 55 52 57 5B 5F 60 60 60 5C 5A 5A 56 52 52 54 97 4E 43 45 49 4D 47 47 56 5E 57 63 7B 85 88 87 74 5E 41 4B 56 3F 45 44 3D 3A 3D 31 36 3C 37 37 38 3D 43 41 43 53 57 5C 60 5F 60 5F 59 58 58 53 55 58 56 1A 45 3B 39 3E 38 43 43 46 4C 47 4A 50 4E 52 53 4D 59 3F 48 54 5A 54 53 4C 51 50 4B 48 45 3F 39 37 3C
					39 01 00 00 00 00 69 CF 40 40 40 40 40 40 40 40 40 40 40 40 40 40 40 40 40 40 40 40 40 40 40 40 40 40 40 40 40 40 40 40 40 40 40 40 40 40 40 40 40 40 40 40 40 40 40 40 40 40 40 40 40 40 40 40 40 40 40 40 40 40 40 40 40 40 40 40 40 40 40 40 40 40 40 40 40 40 40 40 40 40 40 40 40 40 40 40 40 40 40 40 40 40 40 40 40 40 40 40 40 40 40 40
					39 01 00 00 00 00 07 D0 01 00 FE 77 04 1D
					39 01 00 00 00 00 2e D1 4F 4B 40 50 53 53 50 62 4A 70 7F 7F 7F 7F 77 69 40 41 42 40 42 61 40 40 77 55 55 77 65 66 62 66 51 55 45 55 00 06 0C 03 09 0F 68 88 00
					39 01 00 00 00 00 34 D2 01 08 40 83 88 88 83 83 7C 76 73 6D 7C 7A 7C 80 87 87 89 83 8A 85 82 7B 7D 7B 7E 8F 82 84 84 82 7F 7E 7A 56 5F 63 6D 80 92 99 9E B1 8B 84 80 7C 7A 7F 88
					39 01 00 00 00 00 07 D3 30 52 74 76 50 10
					39 01 00 00 00 00 1a D4 0F 76 76 05 0D 14 0F 18 1F 05 0D 14 03 07 0A A0 55 FF 79 44 12 00 00 80 00
					39 01 00 00 00 00 67 D5 00 00 00 00 00 00 40 40 40 40 40 40 40 40 40 40 40 40 40 40 40 40 40 40 40 40 40 40 40 40 40 40 40 40 40 40 40 40 40 40 40 40 40 40 40 40 40 40 40 40 40 40 40 40 40 40 40 40 40 40 40 40 40 40 40 40 40 40 40 40 40 40 40 40 40 40 40 40 40 40 40 40 40 40 40 40 40 40 40 40 40 40 40 40 40 40 40 40 40 40 40 40
					39 01 00 00 00 00 4e D6 00 00 00 00 00 00 00 00 00 00 00 00 40 40 40 40 40 40 40 40 40 40 40 40 40 40 40 40 40 40 40 40 40 40 40 40 40 40 40 40 40 40 40 40 40 40 40 40 40 40 40 40 40 40 40 40 40 40 40 40 40 40 40 40 40 40 40 40 40 40 40 40 40 40 40 40 40
					39 01 00 00 00 00 32 D7 30 34 3A 3C 3B 3D 41 48 4D 46 41 45 3D 38 3B 3C 3D 3D 40 45 47 44 41 43 3D 3C 3C 3C 3E 3C 3F 42 42 42 42 42 3E 3E 3E 3E 3F 3E 3F 41 41 41 41 41 3F
					39 01 00 00 00 00 19 DE 33 63 33 33 33 30 30 33 33 33 30 33 00 00 00 00 00 00 00 00 00 00 00 00
					];
				qcom,mdss-dsi-seed-1-command = [
					39 01 00 00 00 00 02 55 80
					39 01 00 00 00 00 06 F0 55 AA 52 08 00
					39 01 00 00 00 00 19 CC 2D 2A 30 2B 2C 2B 2C 2C 2C 2E 2E 2F 2E 2D 2B 29 27 50 60 70 58 68 78 77
					39 01 00 00 00 00 12 CD 22 50 67 39 22 2D 71 73 21 6A 4A 42 6E 0D 7C 54 45
					39 01 00 00 00 00 68 CE 00 5A 60 5F 4B 51 4A 4B 46 44 46 42 41 3C 39 38 3A 3F 4B 45 5A 4F 4D 55 52 4B 54 64 65 6E 6D 6A 66 61 5D 39 37 46 3D 3B 37 3D 36 34 3F 3E 40 3D 40 40 41 42 39 3F 5A 45 49 42 47 45 41 4C 4A 49 45 43 41 40 40 56 4E 59 4A 4C 4A 50 43 43 46 41 3F 3C 39 38 3B 3E 56 4F 5F 49 49 43 44 3B 3D 40 3D 40 3C 3D 3C 3D 42
					39 01 00 00 00 00 69 CF 40 40 40 40 40 40 40 40 40 40 40 40 40 40 40 40 40 40 40 40 40 40 40 40 40 40 40 40 40 40 40 40 40 40 40 40 40 40 40 40 40 40 40 40 40 40 40 40 40 40 40 40 40 40 40 40 40 40 40 40 40 40 40 40 40 40 40 40 40 40 40 40 40 40 40 40 40 40 40 40 40 40 40 40 40 40 40 40 40 40 40 40 40 40 40 40 40 40 40 40 40 40 40 40
					39 01 00 00 00 00 07 D0 01 00 FE 77 04 1D
					39 01 00 00 00 00 2e D1 60 61 66 72 72 77 7F 72 72 7F 7F 7F 7F 7F 74 5F 51 4F 55 5F 68 66 63 5E 66 46 44 44 54 55 42 50 51 75 74 57 00 06 0C 03 09 0F 68 88 00
					39 01 00 00 00 00 34 D2 01 00 40 8B 8E 8E 88 83 77 69 56 4E 58 64 6F 85 92 94 8E 8F 85 74 6E 66 79 7A 79 9A 7B 80 81 81 80 8F 60 2D 06 38 4F 87 A7 AF A0 B1 87 76 6E 6A 80 8F 9E
					39 01 00 00 00 00 07 D3 30 52 74 76 50 10
					39 01 00 00 00 00 1a D4 0F 76 76 05 0D 14 0F 18 1F 05 0D 14 03 07 0A A0 55 FF 79 44 12 00 00 80 00
					39 01 00 00 00 00 67 D5 00 00 00 00 00 00 40 40 40 40 40 40 40 40 40 40 40 40 40 40 40 40 40 40 40 40 40 40 40 40 40 40 40 40 40 40 40 40 40 40 40 40 40 40 40 40 40 40 40 40 40 40 40 40 40 40 40 40 40 40 40 40 40 40 40 40 40 40 40 40 40 40 40 40 40 40 40 40 40 40 40 40 40 40 40 40 40 40 40 40 40 40 40 40 40 40 40 40 40 40 40 40
					39 01 00 00 00 00 4e D6 00 00 00 00 00 00 00 00 00 00 00 00 40 40 40 40 40 40 40 40 40 40 40 40 40 40 40 40 40 40 40 40 40 40 40 40 40 40 40 40 40 40 40 40 40 40 40 40 40 40 40 40 40 40 40 40 40 40 40 40 40 40 40 40 40 40 40 40 40 40 40 40 40 40 40 40 40
					39 01 00 00 00 00 32 D7 30 39 3C 40 43 46 4B 4F 53 39 49 4E 43 38 3C 3F 41 41 46 4A 4B 3D 44 48 3F 38 3C 3E 40 3D 42 45 44 40 40 42 3C 3C 3E 3F 40 3E 41 42 42 40 40 41 3E
					39 01 00 00 00 00 19 DE 43 45 33 43 40 00 33 34 33 33 37 43 00 00 00 00 00 00 00 00 00 00 00 00
					];
				qcom,mdss-dsi-spr-0-command = [
					39 01 00 00 00 00 06 F0 55 AA 52 08 07
					39 01 00 00 00 00 07 B0 A4 40 70 60 00 00
					39 01 00 00 00 00 18 B1 08 18 00 18 08 00 00 00 00 00 00 00 00 00 00 00 00 00 00 00 00 00 00
					39 01 00 00 00 00 B5 B2 20 20 20 20 20 20 20 20 20 20 20 20 20 20 20 20 20 20 20 20 20 20 20 20 20 20 20 20 20 20 20 20 20 20 20 20 20 20 20 20 20 20 20 20 20 20 20 20 20 20 20 20 20 20 32 32 32 32 32 32 32 32 32 00 00 00 00 00 00 00 00 00 32 32 32 32 32 32 32 32 32 00 00 00 00 00 00 00 00 00 32 32 32 32 32 32 32 32 32 00 00 00 00 00 00 00 00 00 32 32 32 32 32 32 32 32 32 00 00 00 00 00 00 00 00 00 32 32 32 32 32 32 32 32 32 00 00 00 00 00 00 00 00 00 32 32 32 32 32 32 32 32 32 00 00 00 00 00 00 00 00 00 00 00 20 00 20 00 00 00 00 00 32 00 00 00 32 00 00 00
					39 01 00 00 00 00 5B B3 00 00 00 00 00 00 00 00 00 00 00 00 00 00 00 00 00 00 00 00 00 00 00 00 00 00 00 00 00 00 00 00 00 00 00 00 00 00 00 00 00 00 00 00 00 00 00 00 00 00 00 00 00 00 00 00 00 00 00 00 00 00 00 00 00 00 00 00 00 00 00 00 00 00 00 00 00 00 00 00 00 00 00 00 00 00 00 00 00 00
					39 01 00 00 00 00 1B B4 C0 00 00 00 00 00 00 00 00 00 00 00 00 00 80 80 80 80 40 80 80 80 80 80 40 80
					39 01 00 00 00 00 49 B5 00 00 00 00 00 00 00 00 00 00 00 00 00 00 00 00 00 00 00 00 00 00 04 00 00 00 00 00 00 00 00 00 00 00 00 00 00 00 00 00 00 00 00 00 00 00 00 00 00 00 00 00 00 00 00 00 00 00 00 00 00 00 00 00 00 00 00 00 00 00 00 00
					39 01 00 00 00 00 25 B6 00 00 00 00 00 00 00 00 00 00 00 00 00 00 00 00 00 00 00 00 00 00 00 00 E0 00 E0 00 00 00 E0 00 E0 00 00 00
					39 01 00 00 00 00 50 B7 24 84 00 08 01 08 01 00 00 00 00 00 00 00 00 00 00 00 00 00 00 00 00 00 00 00 00 00 00 00 00 00 00 00 00 00 00 00 00 00 00 00 00 FD 58 0E A5 78 2A 1A 77 FE CF 7E 0D E5 B2 B7 87 CC 14 80 80 80 80 80 80 80 80 80 80 80 80 80 80 80 80 80 80
					39 01 00 00 00 00 58 B8 00 00 00 00 00 00 00 00 00 00 00 00 00 00 00 00 00 00 00 02 02 00 00 00 00 00 00 00 00 00 00 00 00 00 00 00 00 00 00 00 00 00 00 00 00 00 00 00 00 00 00 00 00 00 00 00 00 00 00 00 00 00 00 00 00 00 00 00 00 00 00 00 00 00 00 00 00 00 00 00 00 00 00 00 00 00 00
					39 01 00 00 00 00 C1 B9 00 00 00 00 00 00 00 00 00 00 00 00 00 00 00 00 00 00 00 00 00 00 00 00 00 00 00 00 00 00 00 00 00 00 00 00 00 00 00 00 00 00 00 00 00 00 00 00 00 00 00 00 00 00 00 00 00 00 00 00 00 00 00 00 00 00 00 00 00 00 00 00 00 00 00 00 00 00 00 00 00 00 00 00 00 00 00 00 00 00 00 00 00 00 00 00 00 00 00 00 00 00 00 00 00 00 00 00 00 00 00 00 00 00 00 00 00 00 00 00 00 00 00 00 00 00 00 00 00 00 00 00 00 00 00 00 00 00 00 00 00 00 00 00 00 00 00 00 00 00 00 00 00 00 00 00 00 00 00 00 00 00 00 00 00 00 00 00 00 00 00 00 00 00 00 00 00 00 00 00 00 00 00 00 00 00 00 00 00 00 00 00
					39 01 00 00 00 00 20 BA 00 00 00 00 00 00 00 00 00 00 00 00 00 00 00 00 00 00 00 00 00 00 00 00 00 00 00 00 00 00 00
					39 01 00 00 00 00 88 BB 00 00 00 00 00 00 00 00 00 00 00 00 00 00 00 00 00 00 00 00 00 00 00 00 00 00 00 00 00 00 00 00 00 00 00 00 00 00 00 00 00 00 00 00 00 00 00 00 00 00 00 00 00 00 00 00 00 00 00 00 00 00 00 00 00 00 00 00 00 00 00 00 00 00 00 00 00 00 00 00 00 00 00 00 00 00 00 00 00 00 00 00 00 00 00 00 00 00 00 00 00 00 00 00 00 00 00 00 00 00 00 00 00 00 00 00 00 00 00 00 00 00 00 00 00 00 00 00 00 00 00 00 00 00 00
					39 01 00 00 00 00 14 BC 00 00 00 00 00 00 00 00 00 00 00 00 00 00 00 00 00 00 00
					39 01 00 00 00 00 0D BD 00 00 00 00 00 00 00 00 00 00 00 00
					];
				qcom,mdss-dsi-spr-1-command = [
					39 01 00 00 00 00 06 F0 55 AA 52 08 07
					39 01 00 00 00 00 07 B0 A4 40 70 60 00 00
					39 01 00 00 00 00 03 B7 80 90
					39 01 00 00 00 00 02 6F 43
					39 01 00 00 00 00 04 B7 80 70 80
					39 01 00 00 00 00 02 6F 46
					39 01 00 00 00 00 04 B7 80 70 80
					39 01 00 00 00 00 18 B1 0C 1C 00 1C 0C 00 00 00 00 00 00 00 00 00 00 00 00 00 00 00 00 00 00
					39 01 00 00 00 00 B5 B2 22 22 22 22 22 22 22 22 22 22 22 22 22 22 22 22 22 22 00 00 00 00 00 00 00 00 00 22 22 22 22 22 22 22 22 22 22 22 22 22 22 22 22 22 22 00 00 00 00 00 00 00 00 00 3A 3A 3A 3A 3A 3A 3A 3A 3A 05 05 05 05 05 05 05 05 05 3A 3A 3A 3A 3A 3A 3A 3A 3A 05 05 05 05 05 05 05 05 05 00 00 00 00 00 00 00 00 00 00 00 00 00 00 00 00 00 00 3A 3A 3A 3A 3A 3A 3A 3A 3A 05 05 05 05 05 05 05 05 05 3A 3A 3A 3A 3A 3A 3A 3A 3A 05 05 05 05 05 05 05 05 05 00 00 00 00 00 00 00 00 00 00 00 00 00 00 00 00 00 00 00 00 00 00 00 00 00 00 00 00 00 00 00 00 00 00 00 00
					39 01 00 00 00 00 5B B3 00 00 00 00 00 00 00 00 00 00 00 00 00 00 00 00 00 00 00 00 00 00 00 00 00 00 00 00 00 00 00 00 00 00 00 00 00 00 00 00 00 00 00 00 00 00 00 00 00 00 00 00 00 00 00 00 00 00 00 00 00 00 00 00 00 00 00 00 00 00 00 00 00 00 00 00 00 00 00 00 00 00 00 00 00 00 00 00 00 00
					39 01 00 00 00 00 1B B4 C0 00 00 00 00 00 00 00 00 00 00 00 00 00 80 68 80 80 60 80 80 60 80 80 A0 80
					39 01 00 00 00 00 49 B5 00 00 00 00 00 00 00 00 00 00 00 00 00 00 00 00 00 00 00 00 00 00 04 00 00 00 00 00 00 00 00 00 00 00 00 00 00 00 00 00 00 00 00 00 00 00 00 00 00 00 00 00 00 00 00 00 00 00 00 00 00 00 00 00 00 00 00 00 00 00 00 00
					39 01 00 00 00 00 25 B6 00 00 00 00 00 00 00 00 00 00 00 00 00 00 00 00 00 00 00 00 00 00 00 00 E0 00 E0 00 00 00 E0 00 E0 00 00 00
					39 01 00 00 00 00 58 B8 00 00 00 00 00 00 00 00 00 00 00 00 00 00 00 00 00 00 00 02 02 00 00 00 00 00 00 00 00 00 00 00 00 00 00 00 00 00 00 00 00 00 00 00 00 00 00 00 00 00 00 00 00 00 00 00 00 00 00 00 00 00 00 00 00 00 00 00 00 00 00 00 00 00 00 00 00 00 00 00 00 00 00 00 00 00 00
					39 01 00 00 00 00 C1 B9 00 00 00 00 00 00 00 00 00 00 00 00 00 00 00 00 00 00 00 00 00 00 00 00 00 00 00 00 00 00 00 00 00 00 00 00 00 00 00 00 00 00 00 00 00 00 00 00 00 00 00 00 00 00 00 00 00 00 00 00 00 00 00 00 00 00 00 00 00 00 00 00 00 00 00 00 00 00 00 00 00 00 00 00 00 00 00 00 00 00 00 00 00 00 00 00 00 00 00 00 00 00 00 00 00 00 00 00 00 00 00 00 00 00 00 00 00 00 00 00 00 00 00 00 00 00 00 00 00 00 00 00 00 00 00 00 00 00 00 00 00 00 00 00 00 00 00 00 00 00 00 00 00 00 00 00 00 00 00 00 00 00 00 00 00 00 00 00 00 00 00 00 00 00 00 00 00 00 00 00 00 00 00 00 00 00 00 00 00 00 00 00
					39 01 00 00 00 00 20 BA 00 00 00 00 00 00 00 00 00 00 00 00 00 00 00 00 00 00 00 00 00 00 00 00 00 00 00 00 00 00 00
					39 01 00 00 00 00 88 BB 00 00 00 00 00 00 00 00 00 00 00 00 00 00 00 00 00 00 00 00 00 00 00 00 00 00 00 00 00 00 00 00 00 00 00 00 00 00 00 00 00 00 00 00 00 00 00 00 00 00 00 00 00 00 00 00 00 00 00 00 00 00 00 00 00 00 00 00 00 00 00 00 00 00 00 00 00 00 00 00 00 00 00 00 00 00 00 00 00 00 00 00 00 00 00 00 00 00 00 00 00 00 00 00 00 00 00 00 00 00 00 00 00 00 00 00 00 00 00 00 00 00 00 00 00 00 00 00 00 00 00 00 00 00 00
					39 01 00 00 00 00 14 BC 00 00 00 00 00 00 00 00 00 00 00 00 00 00 00 00 00 00 00
					39 01 00 00 00 00 0D BD 00 00 00 00 00 00 00 00 00 00 00 00
					];
				qcom,mdss-dsi-spr-2-command = [
					39 01 00 00 00 00 06 F0 55 AA 52 08 07
					39 01 00 00 00 00 07 B0 A4 40 70 60 00 00
					39 01 00 00 00 00 18 B1 08 18 00 18 08 00 00 00 00 00 00 00 00 00 00 00 00 00 00 00 00 00 00
					39 01 00 00 00 00 B5 B2 20 20 20 20 20 20 20 20 20 20 20 20 20 20 20 20 20 20 20 20 20 20 20 20 20 20 20 20 20 20 20 20 20 20 20 20 20 20 20 20 20 20 20 20 20 20 20 20 20 20 20 20 20 20 03 03 03 03 03 03 03 03 03 00 00 00 00 00 00 00 00 00 03 03 03 03 03 03 03 03 03 00 00 00 00 00 00 00 00 00 03 03 03 03 03 03 03 03 03 00 00 00 00 00 00 00 00 00 03 03 03 03 03 03 03 03 03 00 00 00 00 00 00 00 00 00 03 03 03 03 03 03 03 03 03 00 00 00 00 00 00 00 00 00 03 03 03 03 03 03 03 03 03 00 00 00 00 00 00 00 00 00 00 00 20 00 20 00 00 00 00 00 32 00 00 00 32 00 00 00
					39 01 00 00 00 00 5B B3 00 00 00 00 00 00 00 00 00 00 00 00 00 00 00 00 00 00 00 00 00 00 00 00 00 00 00 00 00 00 00 00 00 00 00 00 00 00 00 00 00 00 00 00 00 00 00 00 00 00 00 00 00 00 00 00 00 00 00 00 00 00 00 00 00 00 00 00 00 00 00 00 00 00 00 00 00 00 00 00 00 00 00 00 00 00 00 00 00 00
					39 01 00 00 00 00 1B B4 C0 00 00 00 00 00 00 00 00 00 00 00 00 00 80 80 80 80 40 80 80 80 80 80 40 80
					39 01 00 00 00 00 49 B5 00 00 00 00 00 00 00 00 00 00 00 00 00 00 00 00 00 00 00 00 00 00 04 00 00 00 00 00 00 00 00 00 00 00 00 00 00 00 00 00 00 00 00 00 00 00 00 00 00 00 00 00 00 00 00 00 00 00 00 00 00 00 00 00 00 00 00 00 00 00 00 00
					39 01 00 00 00 00 25 B6 00 00 00 00 00 00 00 00 00 00 00 00 00 00 00 00 00 00 00 00 00 00 00 00 E0 00 E0 00 00 00 E0 00 E0 00 00 00
					39 01 00 00 00 00 50 B7 24 84 00 08 01 08 01 00 00 00 00 00 00 00 00 00 00 00 00 00 00 00 00 00 00 00 00 00 00 00 00 00 00 00 00 00 00 00 00 00 00 00 00 FD 58 0E A5 78 2A 1A 77 FE CF 7E 0D E5 B2 B7 87 CC 14 80 80 80 80 80 80 80 80 80 80 80 80 80 80 80 80 80 80
					39 01 00 00 00 00 58 B8 00 00 00 00 00 00 00 00 00 00 00 00 00 00 00 00 00 00 00 02 02 00 00 00 00 00 00 00 00 00 00 00 00 00 00 00 00 00 00 00 00 00 00 00 00 00 00 00 00 00 00 00 00 00 00 00 00 00 00 00 00 00 00 00 00 00 00 00 00 00 00 00 00 00 00 00 00 00 00 00 00 00 00 00 00 00 00
					39 01 00 00 00 00 C1 B9 00 00 00 00 00 00 00 00 00 00 00 00 00 00 00 00 00 00 00 00 00 00 00 00 00 00 00 00 00 00 00 00 00 00 00 00 00 00 00 00 00 00 00 00 00 00 00 00 00 00 00 00 00 00 00 00 00 00 00 00 00 00 00 00 00 00 00 00 00 00 00 00 00 00 00 00 00 00 00 00 00 00 00 00 00 00 00 00 00 00 00 00 00 00 00 00 00 00 00 00 00 00 00 00 00 00 00 00 00 00 00 00 00 00 00 00 00 00 00 00 00 00 00 00 00 00 00 00 00 00 00 00 00 00 00 00 00 00 00 00 00 00 00 00 00 00 00 00 00 00 00 00 00 00 00 00 00 00 00 00 00 00 00 00 00 00 00 00 00 00 00 00 00 00 00 00 00 00 00 00 00 00 00 00 00 00 00 00 00 00 00 00
					39 01 00 00 00 00 20 BA 00 00 00 00 00 00 00 00 00 00 00 00 00 00 00 00 00 00 00 00 00 00 00 00 00 00 00 00 00 00 00
					39 01 00 00 00 00 88 BB 00 00 00 00 00 00 00 00 00 00 00 00 00 00 00 00 00 00 00 00 00 00 00 00 00 00 00 00 00 00 00 00 00 00 00 00 00 00 00 00 00 00 00 00 00 00 00 00 00 00 00 00 00 00 00 00 00 00 00 00 00 00 00 00 00 00 00 00 00 00 00 00 00 00 00 00 00 00 00 00 00 00 00 00 00 00 00 00 00 00 00 00 00 00 00 00 00 00 00 00 00 00 00 00 00 00 00 00 00 00 00 00 00 00 00 00 00 00 00 00 00 00 00 00 00 00 00 00 00 00 00 00 00 00 00
					39 01 00 00 00 00 14 BC 00 00 00 00 00 00 00 00 00 00 00 00 00 00 00 00 00 00 00
					39 01 00 00 00 00 0D BD 00 00 00 00 00 00 00 00 00 00 00 00
					];
				qcom,mdss-dsi-data-dimming-on-command = [
					39 00 00 00 00 00 06 F0 55 AA 52 08 00
					39 00 00 00 00 00 02 B2 80
					39 00 00 00 00 00 1E B4
					   00 00 00 00 00 00 00 00 00 00
					   28 28 28 28 28 28 28 28 28 28
					   28 28 28 28 28 28 28 28 28
					39 00 00 00 00 00 25 B3
					   00 00 00 00 00 00 00 00 00 00
					   00 00 00 00 00 00 00 00 00 00
					   00 00 00 00 00 00 00 00 00 00
					   00 00 06 F4 0F FF
				];
				qcom,mdss-dsi-data-dimming-off-command = [
					39 00 00 00 00 00 06 F0 55 AA 52 08 00
					39 00 00 00 00 00 25 B3
					   00 01 00 80 00 80 00 AF 00 AF
					   00 E5 00 E5 01 5B 01 5B 01 F2
					   01 F2 02 58 02 58 03 00 03 00
					   06 F4 06 F4 0F FF
					39 00 00 00 00 00 02 B2 00
					39 00 00 00 00 00 1E B4
					   99 88 88 66 44 22 00 00 00 00
					   40 40 DF DF 1D 1D FC FC E8 E8
					   8C 8C F2 F2 28 28 28 28 28 2C
				];
				qcom,mdss-dsi-data-dimming-on-command-state = "dsi_hs_mode";
				qcom,mdss-dsi-data-dimming-off-command-state = "dsi_hs_mode";
				qcom,mdss-dsi-aod-hbm-on-command-state = "dsi_lp_mode";
				qcom,mdss-dsi-aod-hbm-off-command-state = "dsi_lp_mode";
				qcom,mdss-dsi-hbm-off-command-state = "dsi_hs_mode";
				qcom,mdss-dsi-lp1-command-state = "dsi_lp_mode";
				qcom,mdss-dsi-nolp-command-state = "dsi_lp_mode";
				qcom,mdss-dsi-post-on-backlight-state = "dsi_hs_mode";
				qcom,mdss-dsi-on-command-state = "dsi_lp_mode";
				qcom,mdss-dsi-off-command-state = "dsi_hs_mode";
				qcom,mdss-dsi-normal-hbm-on-command-state = "dsi_hs_mode";
				qcom,mdss-dsi-aod-high-mode-command-state = "dsi_lp_mode";
				qcom,mdss-dsi-aod-low-mode-command-state = "dsi_lp_mode";
				qcom,mdss-dsi-timing-switch-command-state = "dsi_lp_mode";
				qcom,compression-mode = "dsc";
				qcom,mdss-dsc-slice-height = <20>;
				qcom,mdss-dsc-slice-width = <540>;
				qcom,mdss-dsc-slice-per-pkt = <2>;
				qcom,mdss-dsc-bit-per-component = <8>;
				qcom,mdss-dsc-bit-per-pixel = <8>;
				qcom,mdss-dsc-block-prediction-enable;
			};
		};
	};
};

&dsi_oplus19101boe_nt37800_1080_2400_cmd {
	qcom,panel-supply-entries = <&dsi_panel_pwr_supply>;
	qcom,mdss-dsi-bl-pmic-control-type = "bl_ctrl_dcs";
	qcom,mdss-dsi-bl-min-level = <1>;
	qcom,mdss-dsi-bl-normal-max-level = <1780>;
	qcom,mdss-dsi-bl-max-level = <4095>;
	qcom,mdss-brightness-normal-max-level = <1023>;
	qcom,mdss-brightness-max-level = <2047>;
	qcom,mdss-brightness-default-level = <400>;
	qcom,platform-te-gpio = <&tlmm 10 0>;
	qcom,platform-reset-gpio = <&pm8150l_gpios 3 0>;

	oplus,mdss-dsi-vendor-name = "NT37800";
	oplus,mdss-dsi-manufacture = "boe1024";
	oplus,dsi-brightness-remapping = <1 1>,
				<4 18>,
				<5 24>,
				<6 33>,
				<7 38>,
				<8 45>,
				<9 53>,
				<10 59>,
				<11 66>,
				<12 74>,
				<13 81>,
				<14 90>,
				<15 95>,
				<16 106>,
				<17 111>,
				<18 118>,
				<19 127>,
				<20 130>,
				<21 132>,
				<22 133>,
				<26 139>,
				<29 144>,
				<32 149>,
				<36 156>,
				<40 163>,
				<45 170>,
				<51 182>,
				<58 191>,
				<63 200>,
				<67 208>,
				<73 217>,
				<77 226>,
				<81 234>,
				<85 243>,
				<90 252>,
				<96 260>,
				<120 304>,
				<140 339>,
				<150 347>,
				<200 434>,
				<300 521>,
				<400 695>,
				<500 956>,
				<600 1130>,
				<700 1304>,
				<800 1478>,
				<900 1652>,
				<1023 1780>,
				<2047 4095>;

	oplus,dsi-fod-brightness = <0 0xff>,
				<1 0xf0>,
				<2 0xf0>,
				<3 0xef>,
				<6 0xed>,
				<10 0xec>,
				<17 0xeb>,
				<34 0xea>,
				<52 0xe7>,
				<78 0xe3>,
				<121 0xdd>,
				<173 0xca>,
				<260 0xb6>,
				<394 0x9e>,
				<521 0x8e>,
				<695 0x78>,
				<869 0x6a>,
				<1043 0x60>,
				<1391 0x48>,
				<1780 0x28>;

	qcom,ulps-enabled;
	qcom,dsi-select-clocks = "mux_byte_clk0", "mux_pixel_clk0",
				"src_byte_clk0", "src_pixel_clk0",
				"shadow_byte_clk0", "shadow_pixel_clk0";
	qcom,dsi-select-clocks = "mux_byte_clk0", "mux_pixel_clk0";
	qcom,mdss-dsi-t-clk-post = <0x0E>;
	qcom,mdss-dsi-t-clk-pre = <0x35>;
	qcom,mdss-dsi-display-timings {
		timing@0{
			qcom,mdss-dsi-panel-phy-timings = [00 1A 06 06 22 20 07
				06 04 02 04 00 16 16];

			qcom,display-topology = <2 2 1>;
			qcom,default-topology-index = <0>;
		};
		timing@1{
			qcom,mdss-dsi-panel-phy-timings = [00 1A 06 06 22 20 07
				06 04 02 04 00 16 16];

			qcom,display-topology = <2 2 1>;
			qcom,default-topology-index = <0>;
		};
	};
};

&dsi_oplus19101boe_nt37800_1080_2400_cmd {
	qcom,platform-iris-reset-gpio = <&tlmm 84 0>;
	qcom,platform-analog-bypass-gpio = <&tlmm 144 0>;
	qcom,platform-analog-bypass-status-gpio = <&tlmm 145 0>;
	qcom,platform-iris-vdd-gpio = <&tlmm 110 0>;
};
